# GD32F3x0 register map
File version: 1.0
CPU: CM4 r2p1, little endian, no MPU, no FPU, 4 interrupt priority bits
Registers are 32-bit, read-write, reset 0x0 unless marked. A register's access mark holds for its fields unless they carry their own. Offsets are from the block's base; [hi:lo] are bit positions; lines under a group give offsets from that group; {n}, {i} and the like mark numbered series; 'fields as' and 'values as' point back to an identical list.

## TIMER15 — General-purpose-timers
Base 0x40014400
Same registers: TIMER16 0x40014800
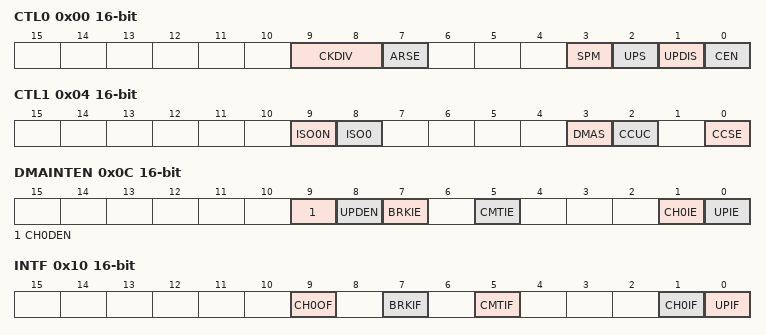
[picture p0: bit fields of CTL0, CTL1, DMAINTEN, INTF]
0x00 CTL0 16-bit — control register 0
  [9:8] CKDIV — Clock division
  [7] ARSE — Auto-reload preload enable
  [3] SPM — One-pulse mode
  [2] UPS — Update request source
  [1] UPDIS — Update disable
  [0] CEN — Counter enable
0x04 CTL1 16-bit — control register 1
  [9] ISO0N — Output Idle state 0
  [8] ISO0 — Output Idle state 0
  [3] DMAS — Capture/compare DMA selection
  [2] CCUC — Capture/compare control update selection
  [0] CCSE — Capture/compare preloaded control
0x0C DMAINTEN 16-bit — DMA/Interrupt enable register
  [9] CH0DEN — Capture/Compare 0 DMA request enable
  [8] UPDEN — Update DMA request enable
  [7] BRKIE — Break interrupt enable
  [5] CMTIE — COM interrupt enable
  [1] CH0IE — Capture/Compare 0 interrupt enable
  [0] UPIE — Update interrupt enable
0x10 INTF 16-bit — interrupt flag register
  [9] CH0OF — Capture/Compare 0 overcapture flag
  [7] BRKIF — Break interrupt flag
  [5] CMTIF — COM interrupt flag
  [1] CH0IF — Capture/compare 0 interrupt flag
  [0] UPIF — Update interrupt flag
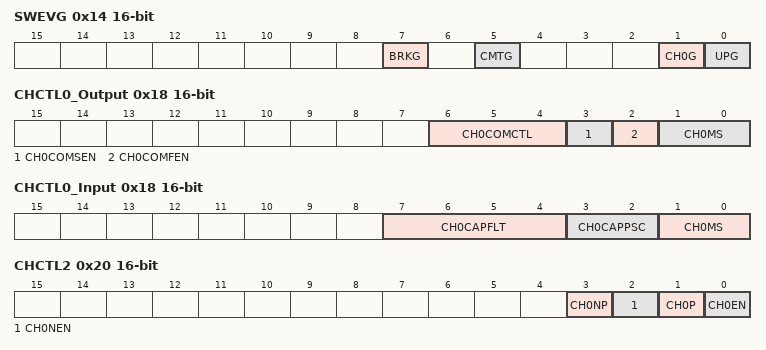
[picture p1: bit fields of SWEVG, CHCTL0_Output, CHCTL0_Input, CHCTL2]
0x14 SWEVG 16-bit wo — event generation register
  [7] BRKG — Break generation
  [5] CMTG — Capture/Compare control update generation
  [1] CH0G — Capture/compare 0 generation
  [0] UPG — Update generation
0x18 CHCTL0_Output 16-bit — capture/compare mode register (output mode)
  [6:4] CH0COMCTL — Output Compare 0 mode
  [3] CH0COMSEN — Output Compare 0 preload enable
  [2] CH0COMFEN — Output Compare 0 fast enable
  [1:0] CH0MS — Capture/Compare 0 selection
0x18 CHCTL0_Input 16-bit (alternate view of CHCTL0_Output) — capture/compare mode register 0 (input mode)
  [7:4] CH0CAPFLT — Input capture 0 filter
  [3:2] CH0CAPPSC — Input capture 0 prescaler
  [1:0] CH0MS — Capture/Compare 0 selection
0x20 CHCTL2 16-bit — capture/compare enable register
  [3] CH0NP — Capture/Compare 0 output Polarity
  [2] CH0NEN — Capture/Compare 0 complementary output enable
  [1] CH0P — Capture/Compare 0 output Polarity
  [0] CH0EN — Capture/Compare 0 output enable
0x24 CNT 16-bit — counter
  [15:0] CNT — counter value
0x28 PSC 16-bit — prescaler
  [15:0] PSC — Prescaler value
0x2C CAR 16-bit — auto-reload register
  [15:0] CARL — Auto-reload value
0x30 CREP 16-bit — repetition counter register
  [7:0] CREP — Repetition counter value
0x34 CH0CV 16-bit — capture/compare register 0
  [15:0] CH0VAL — Capture/Compare 0 value
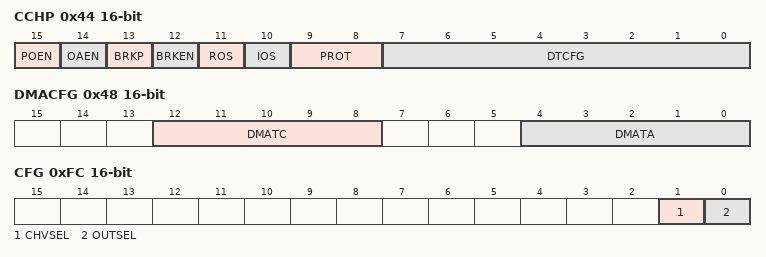
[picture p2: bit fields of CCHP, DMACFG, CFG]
0x44 CCHP 16-bit — break and dead-time register
  [15] POEN — Main output enable
  [14] OAEN — Automatic output enable
  [13] BRKP — Break polarity
  [12] BRKEN — Break enable
  [11] ROS — Off-state selection for Run mode
  [10] IOS — Off-state selection for Idle mode
  [9:8] PROT — complementary register protect control
  [7:0] DTCFG — Dead-time generator setup
0x48 DMACFG 16-bit — DMA configuration register
  [12:8] DMATC — DMA transfer count
  [4:0] DMATA — DMA transfer access start address
0x4C DMATB 16-bit — DMA transfer buffer register
  [15:0] DMATB — DMA register for burst accesses
0xFC CFG 16-bit — configuration register
  [1] CHVSEL — Write CHxVAL register selection
  [0] OUTSEL — The output value selection

## TSI — Touch sensing Interface
Base 0x40024000
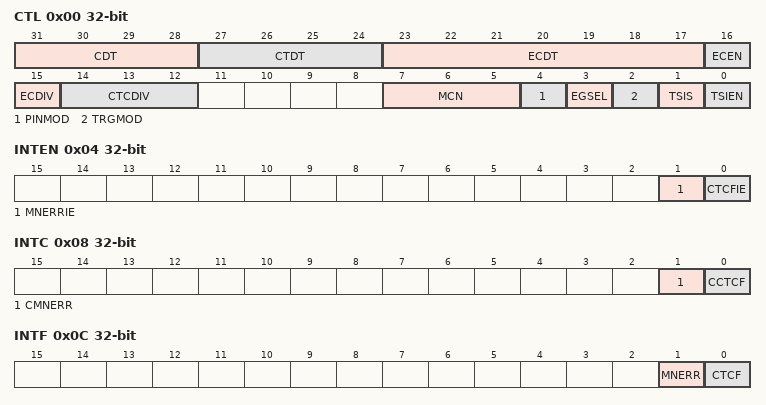
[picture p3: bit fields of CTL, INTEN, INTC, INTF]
0x00 CTL — control register
  [31:28] CDT — Charge transfer pulse high
  [27:24] CTDT — Charge transfer pulse low
  [23:17] ECDT — Spread spectrum deviation
  [16] ECEN — Spread spectrum enable
  [15] ECDIV — Spread spectrum prescaler
  [14:12] CTCDIV — pulse generator prescaler
  [7:5] MCN — Max count value
  [4] PINMOD — I/O Default mode
  [3] EGSEL — Edge selection
  [2] TRGMOD — Trigger mode selection
  [1] TSIS — Start a new acquisition
  [0] TSIEN — Touch sensing controller enable
0x04 INTEN — interrupt enable register
  [1] MNERRIE — Max Cycle Number Error Interrupt Enable
  [0] CTCFIE — Charge-transfer complete flag Interrupt Enable
0x08 INTC — interrupt flag clear register
  [1] CMNERR — Clear max cycle number error
  [0] CCTCF — Clear charge-transfer complete flag
0x0C INTF — interrupt flag register
  [1] MNERR — Max count error flag
  [0] CTCF — End of acquisition flag
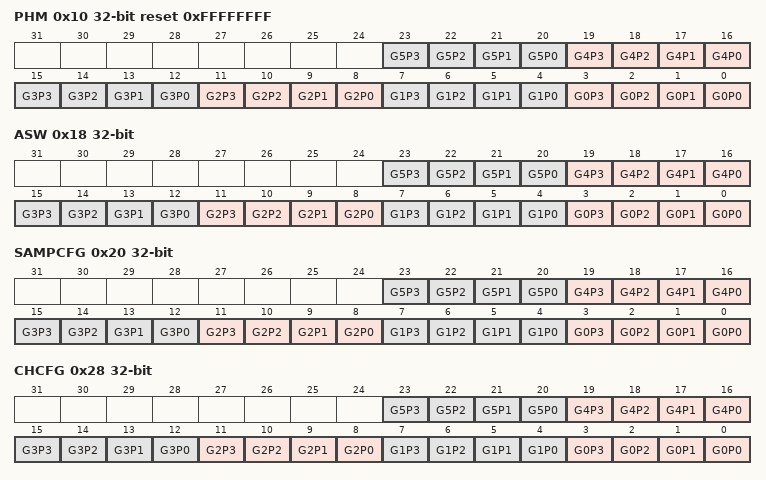
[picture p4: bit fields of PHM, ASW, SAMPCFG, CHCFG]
0x10 PHM reset 0xFFFFFFFF — Pin hysteresis mode register
  [4n+3] G{n}P3 (n=0..5) — G{n}P3 Schmitt trigger hysteresis mode
  [4n+2] G{n}P2 (n=0..5) — G{n}P2 Schmitt trigger hysteresis mode
  [4n+1] G{n}P1 (n=0..5) — G{n}P1 Schmitt trigger hysteresis mode
  [4n] G{n}P0 (n=0..5) — G{n}P0 Schmitt trigger hysteresis mode
0x18 ASW — I/O analog switch register
  [4n+3] G{n}P3 (n=0..5) — G{n}P3 analog switch enable
  [4n+2] G{n}P2 (n=0..5) — G{n}P2 analog switch enable
  [4n+1] G{n}P1 (n=0..5) — G{n}P1 analog switch enable
  [4n] G{n}P0 (n=0..5) — G{n}P0 analog switch enable
0x20 SAMPCFG — I/O sample configuration register
  [4n+3] G{n}P3 (n=0..5) — G{n}P3 sampling mode
  [4n+2] G{n}P2 (n=0..5) — G{n}P2 sampling mode
  [4n+1] G{n}P1 (n=0..5) — G{n}P1 sampling mode
  [4n] G{n}P0 (n=0..5) — G{n}P0 sampling mode
0x28 CHCFG — I/O channel configuration register
  [4n+3] G{n}P3 (n=0..5) — G{n}P3 channel mode
  [4n+2] G{n}P2 (n=0..5) — G{n}P2 channel mode
  [4n+1] G{n}P1 (n=0..5) — G{n}P1 channel mode
  [4n] G{n}P0 (n=0..5) — G{n}P0 channel mode
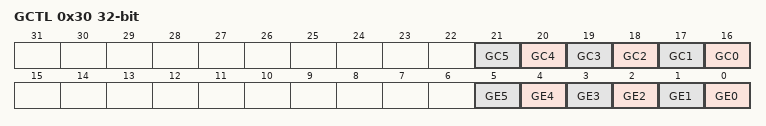
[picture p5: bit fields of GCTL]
0x30 GCTL access per field — I/O group control register
  [n+16] GC{n} ro (n=0..5) — Analog I/O group x status
  [n] GE{n} rw (n=0..5) — Analog I/O group x enable
{0x34+4i} G{i}CYCN ro (i=0..5) — I/O group x cycle number register
  [13:0] CYCN — Cycle number

## WWDGT — Window watchdog timer
Base 0x40002C00
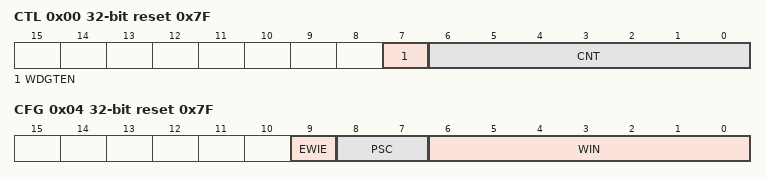
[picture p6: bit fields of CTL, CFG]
0x00 CTL reset 0x7F — Control register
  [7] WDGTEN — Activation bit
  [6:0] CNT — 7-bit counter
0x04 CFG reset 0x7F — Configuration register
  [9] EWIE — Early wakeup interrupt
  [8:7] PSC — Prescaler
  [6:0] WIN — 7-bit window value
0x08 STAT — Status register
  [0] EWIF — Early wakeup interrupt flag

## USBFS_HOST — USB on the go full speed host
Base 0x50000400
0x00 HCTL — host configuration register (HCTL)
  [1:0] CLKSEL — clock select for USB clock
0x04 HFT reset 0xBB80 — Host frame interval register
  [15:0] FRI — Frame interval
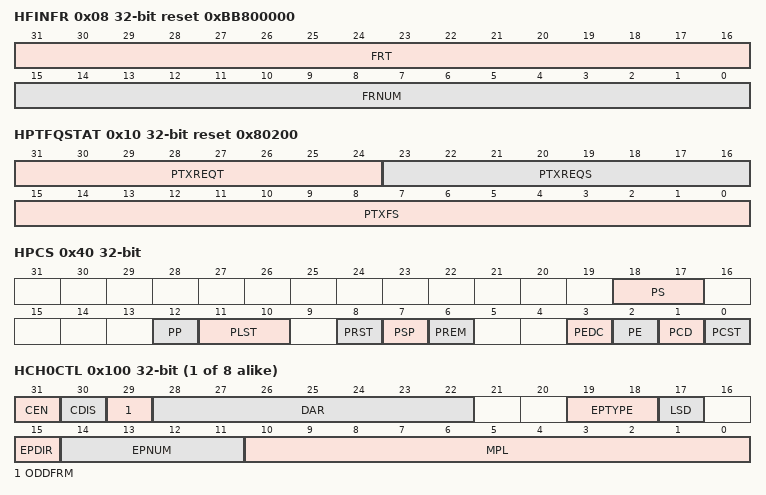
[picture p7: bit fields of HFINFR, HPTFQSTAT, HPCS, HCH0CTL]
0x08 HFINFR ro reset 0xBB800000 — OTG_FS host frame number/frame time remaining register (HFINFR)
  [31:16] FRT — Frame remaining time
  [15:0] FRNUM — Frame number
0x10 HPTFQSTAT ro reset 0x80200 — Host periodic transmit FIFO/queue status register (HPTFQSTAT)
  [31:24] PTXREQT — Top of the periodic transmit request queue
  [23:16] PTXREQS — Periodic transmit request queue space available
  [15:0] PTXFS — Periodic transmit data FIFO space available
0x14 HACHINT ro — Host all channels interrupt register
  [7:0] HACHINT — Host all channel interrupts
0x18 HACHINTEN — host all channels interrupt mask register
  [7:0] CINTEN — Channel interrupt enable
0x40 HPCS access per field — Host port control and status register (USBFS_HPCS)
  [18:17] PS ro — Port speed
  [12] PP rw — Port power
  [11:10] PLST ro — Port line status
  [8] PRST rw — Port reset
  [7] PSP rw — Port suspend
  [6] PREM rw — Port resume
  [3] PEDC rw — Port enable/disable change
  [2] PE rw — Port enable
  [1] PCD rw — Port connect detected
  [0] PCST ro — Port connect status
{0x100+0x20*i} HCH{i}CTL (i=0..7) — host channel-{i} characteristics register (HCH{i}CTL)
  [31] CEN — Channel enable
  [30] CDIS — Channel disable
  [29] ODDFRM — Odd frame
  [28:22] DAR — Device address
  [19:18] EPTYPE — Endpoint type
  [17] LSD — Low-speed device
  [15] EPDIR — Endpoint direction
  [14:11] EPNUM — Endpoint number
  [10:0] MPL — Maximum packet size
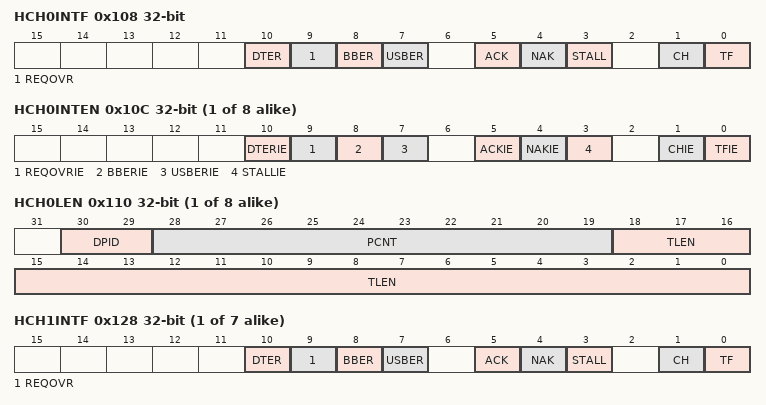
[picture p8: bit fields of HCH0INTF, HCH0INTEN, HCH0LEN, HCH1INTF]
0x108 HCH0INTF — host channel-0 interrupt register (USBFS_HCHxINTF)
  [10] DTER — Data toggle error
  [9] REQOVR — Request queue overrun
  [8] BBER — Babble error
  [7] USBER — USB bus error
  [5] ACK — ACK response received/transmitted interrupt
  [4] NAK — NAK response received interrupt
  [3] STALL — STALL response received interrupt
  [1] CH — Channel halted
  [0] TF — Transfer finished
{0x10C+0x20*i} HCH{i}INTEN (i=0..7) — host channel-{i} interrupt enable register (HCH{i}INTEN)
  [10] DTERIE — Data toggle error interrupt enable
  [9] REQOVRIE — request queue overrun interrupt enable
  [8] BBERIE — Babble error interrupt enable
  [7] USBERIE — USB bus error interrupt enable
  [5] ACKIE — ACK interrupt enable
  [4] NAKIE — NAK interrupt enable
  [3] STALLIE — STALL interrupt enable
  [1] CHIE — Channel halted interrupt enable
  [0] TFIE — Transfer completed interrupt enable
{0x110+0x20*i} HCH{i}LEN (i=0..7) — host channel-{i} transfer length register
  [30:29] DPID — Data PID
  [28:19] PCNT — Packet count
  [18:0] TLEN — Transfer length
{0x108+0x20*i} HCH{i}INTF (i=1..7) — host channel-{i} interrupt register (HCH{i}INTF)
  fields as HCH0INTF

## USBFS_PWRCLK — USB on the go full speed
Base 0x50000E00
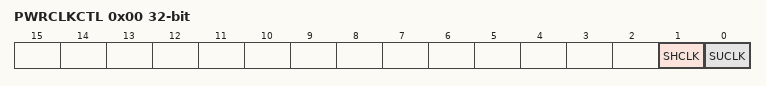
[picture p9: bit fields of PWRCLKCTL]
0x00 PWRCLKCTL — power and clock gating control register (PWRCLKCTL)
  [1] SHCLK — Stop HCLK
  [0] SUCLK — Stop the USB clock
